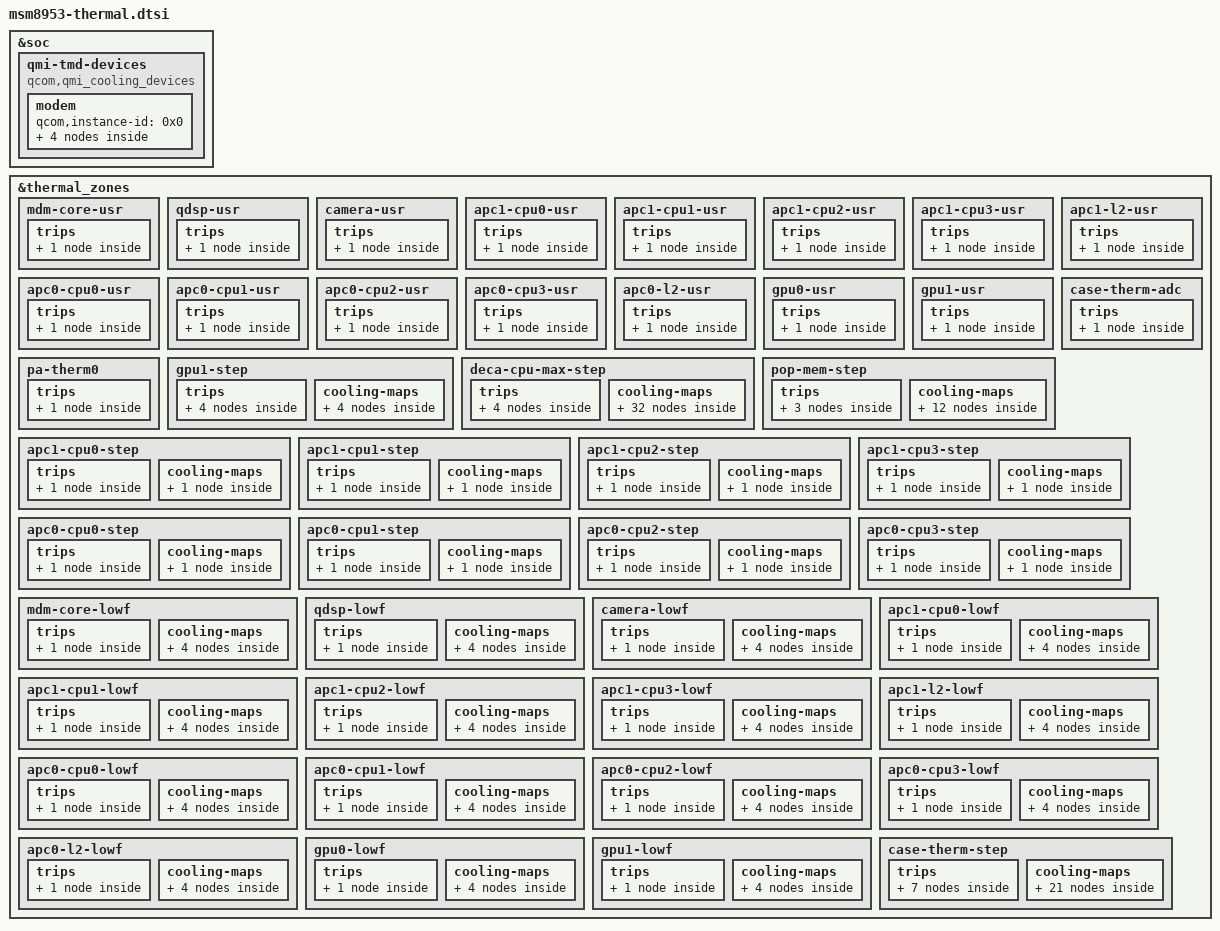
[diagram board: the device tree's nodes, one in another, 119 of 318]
/* Copyright (c) 2018, The Linux Foundation. All rights reserved.
 *
 * This program is free software; you can redistribute it and/or modify
 * it under the terms of the GNU General Public License version 2 and
 * only version 2 as published by the Free Software Foundation.
 *
 * This program is distributed in the hope that it will be useful,
 * but WITHOUT ANY WARRANTY; without even the implied warranty of
 * MERCHANTABILITY or FITNESS FOR A PARTICULAR PURPOSE.  See the
 * GNU General Public License for more details.
 *
 * Optimized thermal configuration for MSM8953
 * Multi-step throttling for smooth performance
 */

#include <dt-bindings/thermal/thermal.h>

&soc {
	qmi-tmd-devices {
		compatible = "qcom,qmi_cooling_devices";

		modem {
			qcom,instance-id = <0x0>;

			modem_pa: modem_pa {
				qcom,qmi-dev-name = "pa";
				#cooling-cells = <2>;
			};

			modem_proc: modem_proc {
				qcom,qmi-dev-name = "modem";
				#cooling-cells = <2>;
			};

			modem_current: modem_current {
				qcom,qmi-dev-name = "modem_current";
				#cooling-cells = <2>;
			};

			modem_vdd: modem_vdd {
				qcom,qmi-dev-name = "cpuv_restriction_cold";
				#cooling-cells = <2>;
			};
		};
	};
};

&thermal_zones {

	/* ═══════════════════════════════════════════════════════════════════
	 * USER-SPACE SENSORS (для чтения приложениями)
	 * ═══════════════════════════════════════════════════════════════════ */

	mdm-core-usr {
		polling-delay-passive = <0>;
		polling-delay = <0>;
		thermal-governor = "user_space";
		thermal-sensors = <&tsens0 1>;
		trips {
			active-config0 {
				temperature = <125000>;
				hysteresis = <1000>;
				type = "passive";
			};
		};
	};

	qdsp-usr {
		polling-delay-passive = <0>;
		polling-delay = <0>;
		thermal-governor = "user_space";
		thermal-sensors = <&tsens0 2>;
		trips {
			active-config0 {
				temperature = <125000>;
				hysteresis = <1000>;
				type = "passive";
			};
		};
	};

	camera-usr {
		polling-delay-passive = <0>;
		polling-delay = <0>;
		thermal-governor = "user_space";
		thermal-sensors = <&tsens0 3>;
		trips {
			active-config0 {
				temperature = <125000>;
				hysteresis = <1000>;
				type = "passive";
			};
		};
	};

	apc1-cpu0-usr {
		polling-delay-passive = <0>;
		polling-delay = <0>;
		thermal-sensors = <&tsens0 4>;
		thermal-governor = "user_space";
		trips {
			active-config0 {
				temperature = <125000>;
				hysteresis = <1000>;
				type = "passive";
			};
		};
	};

	apc1-cpu1-usr {
		polling-delay-passive = <0>;
		polling-delay = <0>;
		thermal-sensors = <&tsens0 5>;
		thermal-governor = "user_space";
		trips {
			active-config0 {
				temperature = <125000>;
				hysteresis = <1000>;
				type = "passive";
			};
		};
	};

	apc1-cpu2-usr {
		polling-delay-passive = <0>;
		polling-delay = <0>;
		thermal-sensors = <&tsens0 6>;
		thermal-governor = "user_space";
		trips {
			active-config0 {
				temperature = <125000>;
				hysteresis = <1000>;
				type = "passive";
			};
		};
	};

	apc1-cpu3-usr {
		polling-delay-passive = <0>;
		polling-delay = <0>;
		thermal-sensors = <&tsens0 7>;
		thermal-governor = "user_space";
		trips {
			active-config0 {
				temperature = <125000>;
				hysteresis = <1000>;
				type = "passive";
			};
		};
	};

	apc1-l2-usr {
		polling-delay-passive = <0>;
		polling-delay = <0>;
		thermal-sensors = <&tsens0 8>;
		thermal-governor = "user_space";
		trips {
			active-config0 {
				temperature = <125000>;
				hysteresis = <1000>;
				type = "passive";
			};
		};
	};

	apc0-cpu0-usr {
		polling-delay-passive = <0>;
		polling-delay = <0>;
		thermal-sensors = <&tsens0 9>;
		thermal-governor = "user_space";
		trips {
			active-config0 {
				temperature = <125000>;
				hysteresis = <1000>;
				type = "passive";
			};
		};
	};

	apc0-cpu1-usr {
		polling-delay-passive = <0>;
		polling-delay = <0>;
		thermal-sensors = <&tsens0 10>;
		thermal-governor = "user_space";
		trips {
			active-config0 {
				temperature = <125000>;
				hysteresis = <1000>;
				type = "passive";
			};
		};
	};

	apc0-cpu2-usr {
		polling-delay-passive = <0>;
		polling-delay = <0>;
		thermal-sensors = <&tsens0 11>;
		thermal-governor = "user_space";
		trips {
			active-config0 {
				temperature = <125000>;
				hysteresis = <1000>;
				type = "passive";
			};
		};
	};

	apc0-cpu3-usr {
		polling-delay-passive = <0>;
		polling-delay = <0>;
		thermal-sensors = <&tsens0 12>;
		thermal-governor = "user_space";
		trips {
			active-config0 {
				temperature = <125000>;
				hysteresis = <1000>;
				type = "passive";
			};
		};
	};

	apc0-l2-usr {
		polling-delay-passive = <0>;
		polling-delay = <0>;
		thermal-sensors = <&tsens0 13>;
		thermal-governor = "user_space";
		trips {
			active-config0 {
				temperature = <125000>;
				hysteresis = <1000>;
				type = "passive";
			};
		};
	};

	gpu0-usr {
		polling-delay-passive = <0>;
		polling-delay = <0>;
		thermal-sensors = <&tsens0 14>;
		thermal-governor = "user_space";
		trips {
			active-config0 {
				temperature = <125000>;
				hysteresis = <1000>;
				type = "passive";
			};
		};
	};

	gpu1-usr {
		polling-delay-passive = <0>;
		polling-delay = <0>;
		thermal-sensors = <&tsens0 15>;
		thermal-governor = "user_space";
		trips {
			active-config0 {
				temperature = <125000>;
				hysteresis = <1000>;
				type = "passive";
			};
		};
	};

	case-therm-adc {
		polling-delay-passive = <0>;
		polling-delay = <0>;
		thermal-sensors = <&pm8953_vadc 0x13>;
		thermal-governor = "user_space";
		trips {
			active-config0 {
				temperature = <65000>;
				hysteresis = <1000>;
				type = "passive";
			};
		};
	};

	pa-therm0 {
		polling-delay-passive = <0>;
		polling-delay = <0>;
		thermal-sensors = <&pm8953_adc_tm 0x36>;
		thermal-governor = "user_space";
		trips {
			active-config0 {
				temperature = <65000>;
				hysteresis = <5000>;
				type = "passive";
			};
		};
	};

	/* ═══════════════════════════════════════════════════════════════════
	 * GPU MULTI-STEP THROTTLING (IMPROVED)
	 * Плавное снижение частоты GPU при нагреве
	 * ═══════════════════════════════════════════════════════════════════ */

	gpu1-step {
		polling-delay-passive = <100>;
		polling-delay = <0>;
		thermal-sensors = <&tsens0 15>;
		thermal-governor = "step_wise";

		trips {
			gpu_trip_mild: gpu-trip-mild {
				temperature = <70000>;
				hysteresis = <3000>;
				type = "passive";
			};

			gpu_trip_moderate: gpu-trip-moderate {
				temperature = <80000>;
				hysteresis = <3000>;
				type = "passive";
			};

			gpu_trip_heavy: gpu-trip-heavy {
				temperature = <90000>;
				hysteresis = <3000>;
				type = "passive";
			};

			gpu_trip0: gpu-trip0 {
				temperature = <95000>;
				hysteresis = <0>;
				type = "passive";
			};
		};

		cooling-maps {
			gpu_cdev_mild {
				trip = <&gpu_trip_mild>;
				cooling-device = <&msm_gpu 1 1>;
			};

			gpu_cdev_moderate {
				trip = <&gpu_trip_moderate>;
				cooling-device = <&msm_gpu 2 3>;
			};

			gpu_cdev_heavy {
				trip = <&gpu_trip_heavy>;
				cooling-device = <&msm_gpu 3 4>;
			};

			gpu_cdev0 {
				trip = <&gpu_trip0>;
				cooling-device = <&msm_gpu THERMAL_NO_LIMIT THERMAL_NO_LIMIT>;
			};
		};
	};

	/* ═══════════════════════════════════════════════════════════════════
	 * CPU MULTI-STEP THROTTLING (IMPROVED)
	 * Плавный throttling начинается с 65°C вместо 95°C
	 * ═══════════════════════════════════════════════════════════════════ */

	deca-cpu-max-step {
		polling-delay-passive = <50>;
		polling-delay = <100>;
		thermal-governor = "step_wise";

		trips {
			/* Мягкий throttling - 65°C */
			cpu_trip_mild: cpu-trip-mild {
				temperature = <65000>;
				hysteresis = <3000>;
				type = "passive";
			};

			/* Умеренный throttling - 75°C */
			cpu_trip_moderate: cpu-trip-moderate {
				temperature = <75000>;
				hysteresis = <3000>;
				type = "passive";
			};

			/* Сильный throttling - 85°C */
			cpu_trip_heavy: cpu-trip-heavy {
				temperature = <85000>;
				hysteresis = <3000>;
				type = "passive";
			};

			/* Критический - 95°C */
			cpu_trip: cpu-trip {
				temperature = <95000>;
				hysteresis = <0>;
				type = "passive";
			};
		};

		cooling-maps {
			/* ══════ 65-75°C: Мягкое ограничение (state 0-2) ══════ */
			/* Ограничение до ~1958 MHz */
			cpu0_mild {
				trip = <&cpu_trip_mild>;
				cooling-device = <&CPU0 0 2>;
			};
			cpu1_mild {
				trip = <&cpu_trip_mild>;
				cooling-device = <&CPU1 0 2>;
			};
			cpu2_mild {
				trip = <&cpu_trip_mild>;
				cooling-device = <&CPU2 0 2>;
			};
			cpu3_mild {
				trip = <&cpu_trip_mild>;
				cooling-device = <&CPU3 0 2>;
			};
			cpu4_mild {
				trip = <&cpu_trip_mild>;
				cooling-device = <&CPU4 0 2>;
			};
			cpu5_mild {
				trip = <&cpu_trip_mild>;
				cooling-device = <&CPU5 0 2>;
			};
			cpu6_mild {
				trip = <&cpu_trip_mild>;
				cooling-device = <&CPU6 0 2>;
			};
			cpu7_mild {
				trip = <&cpu_trip_mild>;
				cooling-device = <&CPU7 0 2>;
			};

			/* ══════ 75-85°C: Умеренное ограничение (state 2-5) ══════ */
			/* Ограничение до ~1689 MHz */
			cpu0_moderate {
				trip = <&cpu_trip_moderate>;
				cooling-device = <&CPU0 2 5>;
			};
			cpu1_moderate {
				trip = <&cpu_trip_moderate>;
				cooling-device = <&CPU1 2 5>;
			};
			cpu2_moderate {
				trip = <&cpu_trip_moderate>;
				cooling-device = <&CPU2 2 5>;
			};
			cpu3_moderate {
				trip = <&cpu_trip_moderate>;
				cooling-device = <&CPU3 2 5>;
			};
			cpu4_moderate {
				trip = <&cpu_trip_moderate>;
				cooling-device = <&CPU4 2 5>;
			};
			cpu5_moderate {
				trip = <&cpu_trip_moderate>;
				cooling-device = <&CPU5 2 5>;
			};
			cpu6_moderate {
				trip = <&cpu_trip_moderate>;
				cooling-device = <&CPU6 2 5>;
			};
			cpu7_moderate {
				trip = <&cpu_trip_moderate>;
				cooling-device = <&CPU7 2 5>;
			};

			/* ══════ 85-95°C: Сильное ограничение (state 5-8) ══════ */
			/* Ограничение до ~1248 MHz */
			cpu0_heavy {
				trip = <&cpu_trip_heavy>;
				cooling-device = <&CPU0 5 8>;
			};
			cpu1_heavy {
				trip = <&cpu_trip_heavy>;
				cooling-device = <&CPU1 5 8>;
			};
			cpu2_heavy {
				trip = <&cpu_trip_heavy>;
				cooling-device = <&CPU2 5 8>;
			};
			cpu3_heavy {
				trip = <&cpu_trip_heavy>;
				cooling-device = <&CPU3 5 8>;
			};
			cpu4_heavy {
				trip = <&cpu_trip_heavy>;
				cooling-device = <&CPU4 5 8>;
			};
			cpu5_heavy {
				trip = <&cpu_trip_heavy>;
				cooling-device = <&CPU5 5 8>;
			};
			cpu6_heavy {
				trip = <&cpu_trip_heavy>;
				cooling-device = <&CPU6 5 8>;
			};
			cpu7_heavy {
				trip = <&cpu_trip_heavy>;
				cooling-device = <&CPU7 5 8>;
			};

			/* ══════ 95°C+: Критическое ограничение ══════ */
			cpu0_cdev {
				trip = <&cpu_trip>;
				cooling-device = <&CPU0 THERMAL_NO_LIMIT (THERMAL_MAX_LIMIT-1)>;
			};
			cpu1_cdev {
				trip = <&cpu_trip>;
				cooling-device = <&CPU1 THERMAL_NO_LIMIT (THERMAL_MAX_LIMIT-1)>;
			};
			cpu2_cdev {
				trip = <&cpu_trip>;
				cooling-device = <&CPU2 THERMAL_NO_LIMIT (THERMAL_MAX_LIMIT-1)>;
			};
			cpu3_cdev {
				trip = <&cpu_trip>;
				cooling-device = <&CPU3 THERMAL_NO_LIMIT (THERMAL_MAX_LIMIT-1)>;
			};
			cpu4_cdev {
				trip = <&cpu_trip>;
				cooling-device = <&CPU4 THERMAL_NO_LIMIT (THERMAL_MAX_LIMIT-1)>;
			};
			cpu5_cdev {
				trip = <&cpu_trip>;
				cooling-device = <&CPU5 THERMAL_NO_LIMIT (THERMAL_MAX_LIMIT-1)>;
			};
			cpu6_cdev {
				trip = <&cpu_trip>;
				cooling-device = <&CPU6 THERMAL_NO_LIMIT (THERMAL_MAX_LIMIT-1)>;
			};
			cpu7_cdev {
				trip = <&cpu_trip>;
				cooling-device = <&CPU7 THERMAL_NO_LIMIT (THERMAL_MAX_LIMIT-1)>;
			};
		};
	};

	/* ═══════════════════════════════════════════════════════════════════
	 * MEMORY/POP THERMAL (IMPROVED)
	 * ═══════════════════════════════════════════════════════════════════ */

	pop-mem-step {
		polling-delay-passive = <250>;
		polling-delay = <0>;
		thermal-sensors = <&tsens0 2>;
		thermal-governor = "step_wise";

		trips {
			pop_trip_mild: pop-trip-mild {
				temperature = <75000>;
				hysteresis = <3000>;
				type = "passive";
			};

			pop_trip_moderate: pop-trip-moderate {
				temperature = <85000>;
				hysteresis = <3000>;
				type = "passive";
			};

			pop_trip: pop-trip {
				temperature = <95000>;
				hysteresis = <0>;
				type = "passive";
			};
		};

		cooling-maps {
			pop_cdev0_mild {
				trip = <&pop_trip_mild>;
				cooling-device = <&CPU0 0 3>;
			};
			pop_cdev4_mild {
				trip = <&pop_trip_mild>;
				cooling-device = <&CPU4 0 3>;
			};

			pop_cdev0_moderate {
				trip = <&pop_trip_moderate>;
				cooling-device = <&CPU0 3 6>;
			};
			pop_cdev4_moderate {
				trip = <&pop_trip_moderate>;
				cooling-device = <&CPU4 3 6>;
			};

			pop_cdev0 {
				trip = <&pop_trip>;
				cooling-device = <&CPU0 THERMAL_NO_LIMIT (THERMAL_MAX_LIMIT-1)>;
			};
			pop_cdev1 {
				trip = <&pop_trip>;
				cooling-device = <&CPU1 THERMAL_NO_LIMIT (THERMAL_MAX_LIMIT-1)>;
			};
			pop_cdev2 {
				trip = <&pop_trip>;
				cooling-device = <&CPU2 THERMAL_NO_LIMIT (THERMAL_MAX_LIMIT-1)>;
			};
			pop_cdev3 {
				trip = <&pop_trip>;
				cooling-device = <&CPU3 THERMAL_NO_LIMIT (THERMAL_MAX_LIMIT-1)>;
			};
			pop_cdev4 {
				trip = <&pop_trip>;
				cooling-device = <&CPU4 THERMAL_NO_LIMIT (THERMAL_MAX_LIMIT-1)>;
			};
			pop_cdev5 {
				trip = <&pop_trip>;
				cooling-device = <&CPU5 THERMAL_NO_LIMIT (THERMAL_MAX_LIMIT-1)>;
			};
			pop_cdev6 {
				trip = <&pop_trip>;
				cooling-device = <&CPU6 THERMAL_NO_LIMIT (THERMAL_MAX_LIMIT-1)>;
			};
			pop_cdev7 {
				trip = <&pop_trip>;
				cooling-device = <&CPU7 THERMAL_NO_LIMIT (THERMAL_MAX_LIMIT-1)>;
			};
		};
	};

	/* ═══════════════════════════════════════════════════════════════════
	 * PER-CPU EMERGENCY THROTTLING (IMPROVED)
	 * Порог снижен до 100°C для безопасности
	 * ═══════════════════════════════════════════════════════════════════ */

	apc1-cpu0-step {
		polling-delay-passive = <0>;
		polling-delay = <0>;
		thermal-sensors = <&tsens0 4>;
		thermal-governor = "step_wise";
		trips {
			apc1_cpu0_trip: apc1-cpu0-trip {
				temperature = <100000>;
				hysteresis = <10000>;
				type = "passive";
			};
		};
		cooling-maps {
			cpu4_cdev {
				trip = <&apc1_cpu0_trip>;
				cooling-device = <&CPU4 THERMAL_MAX_LIMIT THERMAL_MAX_LIMIT>;
			};
		};
	};

	apc1-cpu1-step {
		polling-delay-passive = <0>;
		polling-delay = <0>;
		thermal-sensors = <&tsens0 5>;
		thermal-governor = "step_wise";
		trips {
			apc1_cpu1_trip: apc1-cpu1-trip {
				temperature = <100000>;
				hysteresis = <10000>;
				type = "passive";
			};
		};
		cooling-maps {
			cpu5_cdev {
				trip = <&apc1_cpu1_trip>;
				cooling-device = <&CPU5 THERMAL_MAX_LIMIT THERMAL_MAX_LIMIT>;
			};
		};
	};

	apc1-cpu2-step {
		polling-delay-passive = <0>;
		polling-delay = <0>;
		thermal-sensors = <&tsens0 6>;
		thermal-governor = "step_wise";
		trips {
			apc1_cpu2_trip: apc1-cpu2-trip {
				temperature = <100000>;
				hysteresis = <10000>;
				type = "passive";
			};
		};
		cooling-maps {
			cpu6_cdev {
				trip = <&apc1_cpu2_trip>;
				cooling-device = <&CPU6 THERMAL_MAX_LIMIT THERMAL_MAX_LIMIT>;
			};
		};
	};

	apc1-cpu3-step {
		polling-delay-passive = <0>;
		polling-delay = <0>;
		thermal-sensors = <&tsens0 7>;
		thermal-governor = "step_wise";
		trips {
			apc1_cpu3_trip: apc1-cpu3-trip {
				temperature = <100000>;
				hysteresis = <10000>;
				type = "passive";
			};
		};
		cooling-maps {
			cpu7_cdev {
				trip = <&apc1_cpu3_trip>;
				cooling-device = <&CPU7 THERMAL_MAX_LIMIT THERMAL_MAX_LIMIT>;
			};
		};
	};

	apc0-cpu0-step {
		polling-delay-passive = <0>;
		polling-delay = <0>;
		thermal-sensors = <&tsens0 9>;
		thermal-governor = "step_wise";
		trips {
			apc0_cpu0_trip: apc0-cpu0-trip {
				temperature = <100000>;
				hysteresis = <10000>;
				type = "passive";
			};
		};
		cooling-maps {
			cpu0_cdev {
				trip = <&apc0_cpu0_trip>;
				cooling-device = <&CPU0 THERMAL_MAX_LIMIT THERMAL_MAX_LIMIT>;
			};
		};
	};

	apc0-cpu1-step {
		polling-delay-passive = <0>;
		polling-delay = <0>;
		thermal-sensors = <&tsens0 10>;
		thermal-governor = "step_wise";
		trips {
			apc0_cpu1_trip: apc0-cpu1-trip {
				temperature = <100000>;
				hysteresis = <10000>;
				type = "passive";
			};
		};
		cooling-maps {
			cpu1_cdev {
				trip = <&apc0_cpu1_trip>;
				cooling-device = <&CPU1 THERMAL_MAX_LIMIT THERMAL_MAX_LIMIT>;
			};
		};
	};

	apc0-cpu2-step {
		polling-delay-passive = <0>;
		polling-delay = <0>;
		thermal-sensors = <&tsens0 11>;
		thermal-governor = "step_wise";
		trips {
			apc0_cpu2_trip: apc0-cpu2-trip {
				temperature = <100000>;
				hysteresis = <10000>;
				type = "passive";
			};
		};
		cooling-maps {
			cpu2_cdev {
				trip = <&apc0_cpu2_trip>;
				cooling-device = <&CPU2 THERMAL_MAX_LIMIT THERMAL_MAX_LIMIT>;
			};
		};
	};

	apc0-cpu3-step {
		polling-delay-passive = <0>;
		polling-delay = <0>;
		thermal-sensors = <&tsens0 12>;
		thermal-governor = "step_wise";
		trips {
			apc0_cpu3_trip: apc0-cpu3-trip {
				temperature = <100000>;
				hysteresis = <10000>;
				type = "passive";
			};
		};
		cooling-maps {
			cpu3_cdev {
				trip = <&apc0_cpu3_trip>;
				cooling-device = <&CPU3 THERMAL_MAX_LIMIT THERMAL_MAX_LIMIT>;
			};
		};
	};

	/* ═══════════════════════════════════════════════════════════════════
	 * LOW TEMPERATURE FLOOR PROTECTION
	 * Защита от работы на слишком низких температурах
	 * ═══════════════════════════════════════════════════════════════════ */

	mdm-core-lowf {
		polling-delay-passive = <0>;
		polling-delay = <0>;
		thermal-governor = "low_limits_floor";
		thermal-sensors = <&tsens0 1>;
		tracks-low;
		trips {
			mdm_core_trip: mdm-core-trip {
				temperature = <5000>;
				hysteresis = <5000>;
				type = "passive";
			};
		};
		cooling-maps {
			cpu0_vdd_cdev {
				trip = <&mdm_core_trip>;
				cooling-device = <&CPU0 (THERMAL_MAX_LIMIT - 4)
						(THERMAL_MAX_LIMIT - 4)>;
			};
			gpu_vdd_cdev {
				trip = <&mdm_core_trip>;
				cooling-device = <&msm_gpu 2 2>;
			};
			cx_vdd_cdev {
				trip = <&mdm_core_trip>;
				cooling-device = <&cx_cdev 0 0>;
			};
			modem_vdd_cdev {
				trip = <&mdm_core_trip>;
				cooling-device = <&modem_vdd 0 0>;
			};
		};
	};

	qdsp-lowf {
		polling-delay-passive = <0>;
		polling-delay = <0>;
		thermal-governor = "low_limits_floor";
		thermal-sensors = <&tsens0 2>;
		tracks-low;
		trips {
			qdsp_trip: qdsp-trip {
				temperature = <5000>;
				hysteresis = <5000>;
				type = "passive";
			};
		};
		cooling-maps {
			cpu0_vdd_cdev {
				trip = <&qdsp_trip>;
				cooling-device = <&CPU0 (THERMAL_MAX_LIMIT - 4)
						(THERMAL_MAX_LIMIT - 4)>;
			};
			gpu_vdd_cdev {
				trip = <&qdsp_trip>;
				cooling-device = <&msm_gpu 2 2>;
			};
			cx_vdd_cdev {
				trip = <&qdsp_trip>;
				cooling-device = <&cx_cdev 0 0>;
			};
			modem_vdd_cdev {
				trip = <&qdsp_trip>;
				cooling-device = <&modem_vdd 0 0>;
			};
		};
	};

	camera-lowf {
		polling-delay-passive = <0>;
		polling-delay = <0>;
		thermal-governor = "low_limits_floor";
		thermal-sensors = <&tsens0 3>;
		tracks-low;
		trips {
			camera_trip: camera-trip {
				temperature = <5000>;
				hysteresis = <5000>;
				type = "passive";
			};
		};
		cooling-maps {
			cpu0_vdd_cdev {
				trip = <&camera_trip>;
				cooling-device = <&CPU0 (THERMAL_MAX_LIMIT - 4)
						(THERMAL_MAX_LIMIT - 4)>;
			};
			gpu_vdd_cdev {
				trip = <&camera_trip>;
				cooling-device = <&msm_gpu 2 2>;
			};
			cx_vdd_cdev {
				trip = <&camera_trip>;
				cooling-device = <&cx_cdev 0 0>;
			};
			modem_vdd_cdev {
				trip = <&camera_trip>;
				cooling-device = <&modem_vdd 0 0>;
			};
		};
	};

	apc1-cpu0-lowf {
		polling-delay-passive = <0>;
		polling-delay = <0>;
		thermal-governor = "low_limits_floor";
		thermal-sensors = <&tsens0 4>;
		tracks-low;
		trips {
			cpu4_trip: apc1-cpu0-trip {
				temperature = <5000>;
				hysteresis = <5000>;
				type = "passive";
			};
		};
		cooling-maps {
			cpu0_vdd_cdev {
				trip = <&cpu4_trip>;
				cooling-device = <&CPU0 (THERMAL_MAX_LIMIT - 4)
						(THERMAL_MAX_LIMIT - 4)>;
			};
			gpu_vdd_cdev {
				trip = <&cpu4_trip>;
				cooling-device = <&msm_gpu 2 2>;
			};
			cx_vdd_cdev {
				trip = <&cpu4_trip>;
				cooling-device = <&cx_cdev 0 0>;
			};
			modem_vdd_cdev {
				trip = <&cpu4_trip>;
				cooling-device = <&modem_vdd 0 0>;
			};
		};
	};

	apc1-cpu1-lowf {
		polling-delay-passive = <0>;
		polling-delay = <0>;
		thermal-governor = "low_limits_floor";
		thermal-sensors = <&tsens0 5>;
		tracks-low;
		trips {
			cpu5_trip: apc1-cpu0-trip {
				temperature = <5000>;
				hysteresis = <5000>;
				type = "passive";
			};
		};
		cooling-maps {
			cpu0_vdd_cdev {
				trip = <&cpu5_trip>;
				cooling-device = <&CPU0 (THERMAL_MAX_LIMIT - 4)
						(THERMAL_MAX_LIMIT - 4)>;
			};
			gpu_vdd_cdev {
				trip = <&cpu5_trip>;
				cooling-device = <&msm_gpu 2 2>;
			};
			cx_vdd_cdev {
				trip = <&cpu5_trip>;
				cooling-device = <&cx_cdev 0 0>;
			};
			modem_vdd_cdev {
				trip = <&cpu5_trip>;
				cooling-device = <&modem_vdd 0 0>;
			};
		};
	};

	apc1-cpu2-lowf {
		polling-delay-passive = <0>;
		polling-delay = <0>;
		thermal-governor = "low_limits_floor";
		thermal-sensors = <&tsens0 6>;
		tracks-low;
		trips {
			cpu6_trip: apc1-cpu2-trip {
				temperature = <5000>;
				hysteresis = <5000>;
				type = "passive";
			};
		};
		cooling-maps {
			cpu0_vdd_cdev {
				trip = <&cpu6_trip>;
				cooling-device = <&CPU0 (THERMAL_MAX_LIMIT - 4)
						(THERMAL_MAX_LIMIT - 4)>;
			};
			gpu_vdd_cdev {
				trip = <&cpu6_trip>;
				cooling-device = <&msm_gpu 2 2>;
			};
			cx_vdd_cdev {
				trip = <&cpu6_trip>;
				cooling-device = <&cx_cdev 0 0>;
			};
			modem_vdd_cdev {
				trip = <&cpu6_trip>;
				cooling-device = <&modem_vdd 0 0>;
			};
		};
	};

	apc1-cpu3-lowf {
		polling-delay-passive = <0>;
		polling-delay = <0>;
		thermal-governor = "low_limits_floor";
		thermal-sensors = <&tsens0 7>;
		tracks-low;
		trips {
			cpu7_trip: apc1-cpu3-trip {
				temperature = <5000>;
				hysteresis = <5000>;
				type = "passive";
			};
		};
		cooling-maps {
			cpu0_vdd_cdev {
				trip = <&cpu7_trip>;
				cooling-device = <&CPU0 (THERMAL_MAX_LIMIT - 4)
						(THERMAL_MAX_LIMIT - 4)>;
			};
			gpu_vdd_cdev {
				trip = <&cpu7_trip>;
				cooling-device = <&msm_gpu 2 2>;
			};
			cx_vdd_cdev {
				trip = <&cpu7_trip>;
				cooling-device = <&cx_cdev 0 0>;
			};
			modem_vdd_cdev {
				trip = <&cpu7_trip>;
				cooling-device = <&modem_vdd 0 0>;
			};
		};
	};

	apc1-l2-lowf {
		polling-delay-passive = <0>;
		polling-delay = <0>;
		thermal-governor = "low_limits_floor";
		thermal-sensors = <&tsens0 8>;
		tracks-low;
		trips {
			apc1_l2_trip: apc1-l2-trip {
				temperature = <5000>;
				hysteresis = <5000>;
				type = "passive";
			};
		};
		cooling-maps {
			cpu0_vdd_cdev {
				trip = <&apc1_l2_trip>;
				cooling-device = <&CPU0 (THERMAL_MAX_LIMIT - 4)
						(THERMAL_MAX_LIMIT - 4)>;
			};
			gpu_vdd_cdev {
				trip = <&apc1_l2_trip>;
				cooling-device = <&msm_gpu 2 2>;
			};
			cx_vdd_cdev {
				trip = <&apc1_l2_trip>;
				cooling-device = <&cx_cdev 0 0>;
			};
			modem_vdd_cdev {
				trip = <&apc1_l2_trip>;
				cooling-device = <&modem_vdd 0 0>;
			};
		};
	};

	apc0-cpu0-lowf {
		polling-delay-passive = <0>;
		polling-delay = <0>;
		thermal-governor = "low_limits_floor";
		thermal-sensors = <&tsens0 9>;
		tracks-low;
		trips {
			cpu0_trip: apc0-cpu0-trip {
				temperature = <5000>;
				hysteresis = <5000>;
				type = "passive";
			};
		};
		cooling-maps {
			cpu0_vdd_cdev {
				trip = <&cpu0_trip>;
				cooling-device = <&CPU0 (THERMAL_MAX_LIMIT - 4)
						(THERMAL_MAX_LIMIT - 4)>;
			};
			gpu_vdd_cdev {
				trip = <&cpu0_trip>;
				cooling-device = <&msm_gpu 2 2>;
			};
			cx_vdd_cdev {
				trip = <&cpu0_trip>;
				cooling-device = <&cx_cdev 0 0>;
			};
			modem_vdd_cdev {
				trip = <&cpu0_trip>;
				cooling-device = <&modem_vdd 0 0>;
			};
		};
	};

	apc0-cpu1-lowf {
		polling-delay-passive = <0>;
		polling-delay = <0>;
		thermal-governor = "low_limits_floor";
		thermal-sensors = <&tsens0 10>;
		tracks-low;
		trips {
			cpu1_trip: apc0-cpu1-trip {
				temperature = <5000>;
				hysteresis = <5000>;
				type = "passive";
			};
		};
		cooling-maps {
			cpu0_vdd_cdev {
				trip = <&cpu1_trip>;
				cooling-device = <&CPU0 (THERMAL_MAX_LIMIT - 4)
						(THERMAL_MAX_LIMIT - 4)>;
			};
			gpu_vdd_cdev {
				trip = <&cpu1_trip>;
				cooling-device = <&msm_gpu 2 2>;
			};
			cx_vdd_cdev {
				trip = <&cpu1_trip>;
				cooling-device = <&cx_cdev 0 0>;
			};
			modem_vdd_cdev {
				trip = <&cpu1_trip>;
				cooling-device = <&modem_vdd 0 0>;
			};
		};
	};

	apc0-cpu2-lowf {
		polling-delay-passive = <0>;
		polling-delay = <0>;
		thermal-governor = "low_limits_floor";
		thermal-sensors = <&tsens0 11>;
		tracks-low;
		trips {
			cpu2_trip: apc0-cpu2-trip {
				temperature = <5000>;
				hysteresis = <5000>;
				type = "passive";
			};
		};
		cooling-maps {
			cpu0_vdd_cdev {
				trip = <&cpu2_trip>;
				cooling-device = <&CPU0 (THERMAL_MAX_LIMIT - 4)
						(THERMAL_MAX_LIMIT - 4)>;
			};
			gpu_vdd_cdev {
				trip = <&cpu2_trip>;
				cooling-device = <&msm_gpu 2 2>;
			};
			cx_vdd_cdev {
				trip = <&cpu2_trip>;
				cooling-device = <&cx_cdev 0 0>;
			};
			modem_vdd_cdev {
				trip = <&cpu2_trip>;
				cooling-device = <&modem_vdd 0 0>;
			};
		};
	};

	apc0-cpu3-lowf {
		polling-delay-passive = <0>;
		polling-delay = <0>;
		thermal-governor = "low_limits_floor";
		thermal-sensors = <&tsens0 12>;
		tracks-low;
		trips {
			cpu3_trip: apc0-cpu3-trip {
				temperature = <5000>;
				hysteresis = <5000>;
				type = "passive";
			};
		};
		cooling-maps {
			cpu0_vdd_cdev {
				trip = <&cpu3_trip>;
				cooling-device = <&CPU0 (THERMAL_MAX_LIMIT - 4)
						(THERMAL_MAX_LIMIT - 4)>;
			};
			gpu_vdd_cdev {
				trip = <&cpu3_trip>;
				cooling-device = <&msm_gpu 2 2>;
			};
			cx_vdd_cdev {
				trip = <&cpu3_trip>;
				cooling-device = <&cx_cdev 0 0>;
			};
			modem_vdd_cdev {
				trip = <&cpu3_trip>;
				cooling-device = <&modem_vdd 0 0>;
			};
		};
	};

	apc0-l2-lowf {
		polling-delay-passive = <0>;
		polling-delay = <0>;
		thermal-governor = "low_limits_floor";
		thermal-sensors = <&tsens0 13>;
		tracks-low;
		trips {
			apc0_l2_trip: apc0-l2-trip {
				temperature = <5000>;
				hysteresis = <5000>;
				type = "passive";
			};
		};
		cooling-maps {
			cpu0_vdd_cdev {
				trip = <&apc0_l2_trip>;
				cooling-device = <&CPU0 (THERMAL_MAX_LIMIT - 4)
						(THERMAL_MAX_LIMIT - 4)>;
			};
			gpu_vdd_cdev {
				trip = <&apc0_l2_trip>;
				cooling-device = <&msm_gpu 2 2>;
			};
			cx_vdd_cdev {
				trip = <&apc0_l2_trip>;
				cooling-device = <&cx_cdev 0 0>;
			};
			modem_vdd_cdev {
				trip = <&apc0_l2_trip>;
				cooling-device = <&modem_vdd 0 0>;
			};
		};
	};

	gpu0-lowf {
		polling-delay-passive = <0>;
		polling-delay = <0>;
		thermal-governor = "low_limits_floor";
		thermal-sensors = <&tsens0 14>;
		tracks-low;
		trips {
			gpu0_trip: gpu0-trip {
				temperature = <5000>;
				hysteresis = <5000>;
				type = "passive";
			};
		};
		cooling-maps {
			cpu0_vdd_cdev {
				trip = <&gpu0_trip>;
				cooling-device = <&CPU0 (THERMAL_MAX_LIMIT - 4)
						(THERMAL_MAX_LIMIT - 4)>;
			};
			gpu_vdd_cdev {
				trip = <&gpu0_trip>;
				cooling-device = <&msm_gpu 2 2>;
			};
			cx_vdd_cdev {
				trip = <&gpu0_trip>;
				cooling-device = <&cx_cdev 0 0>;
			};
			modem_vdd_cdev {
				trip = <&gpu0_trip>;
				cooling-device = <&modem_vdd 0 0>;
			};
		};
	};

	gpu1-lowf {
		polling-delay-passive = <0>;
		polling-delay = <0>;
		thermal-governor = "low_limits_floor";
		thermal-sensors = <&tsens0 15>;
		tracks-low;
		trips {
			gpu1_trip: gpu1-trip {
				temperature = <5000>;
				hysteresis = <5000>;
				type = "passive";
			};
		};
		cooling-maps {
			cpu0_vdd_cdev {
				trip = <&gpu1_trip>;
				cooling-device = <&CPU0 (THERMAL_MAX_LIMIT - 4)
						(THERMAL_MAX_LIMIT - 4)>;
			};
			gpu_vdd_cdev {
				trip = <&gpu1_trip>;
				cooling-device = <&msm_gpu 2 2>;
			};
			cx_vdd_cdev {
				trip = <&gpu1_trip>;
				cooling-device = <&cx_cdev 0 0>;
			};
			modem_vdd_cdev {
				trip = <&gpu1_trip>;
				cooling-device = <&modem_vdd 0 0>;
			};
		};
	};

	/* ═══════════════════════════════════════════════════════════════════
	 * CASE/SKIN THERMAL (IMPROVED)
	 * Плавный throttling на основе температуры корпуса
	 * ═══════════════════════════════════════════════════════════════════ */

	case-therm-step {
		polling-delay-passive = <1000>;
		polling-delay = <0>;
		thermal-sensors = <&pm8953_vadc 0x13>;
		thermal-governor = "step_wise";

		trips {
			/* Раннее предупреждение - 45°C на корпусе */
			skin_trip_early: skin-trip-early {
				temperature = <45000>;
				hysteresis = <2000>;
				type = "passive";
			};

			/* Мягкое ограничение - 50°C на корпусе */
			skin_trip_mild: skin-trip-mild {
				temperature = <50000>;
				hysteresis = <2000>;
				type = "passive";
			};

			/* Умеренное ограничение - 55°C */
			skin_trip_moderate: skin-trip-moderate {
				temperature = <55000>;
				hysteresis = <2000>;
				type = "passive";
			};

			/* Оригинальный trip - 60°C */
			cpus_trip: cpus-trip {
				temperature = <60000>;
				hysteresis = <0>;
				type = "passive";
			};

			modem_trip0: modem-trip0 {
				temperature = <70000>;
				hysteresis = <2000>;
				type = "passive";
			};

			modem_trip1: modem-trip1 {
				temperature = <72000>;
				hysteresis = <3000>;
				type = "passive";
			};

			modem_trip2: modem-trip2 {
				temperature = <75000>;
				hysteresis = <4000>;
				type = "critical";
			};
		};

		cooling-maps {
			/* ══════ 45-50°C: Очень мягкое ограничение ══════ */
			skin_cpu0_early {
				trip = <&skin_trip_early>;
				cooling-device = <&CPU0 0 1>;
			};
			skin_cpu4_early {
				trip = <&skin_trip_early>;
				cooling-device = <&CPU4 0 1>;
			};

			/* ══════ 50-55°C: Мягкое ограничение ══════ */
			skin_cpu0_mild {
				trip = <&skin_trip_mild>;
				cooling-device = <&CPU0 1 2>;
			};
			skin_cpu4_mild {
				trip = <&skin_trip_mild>;
				cooling-device = <&CPU4 1 2>;
			};
			skin_gpu_mild {
				trip = <&skin_trip_mild>;
				cooling-device = <&msm_gpu 0 1>;
			};

			/* ══════ 55-60°C: Умеренное ограничение ══════ */
			skin_cpu0_moderate {
				trip = <&skin_trip_moderate>;
				cooling-device = <&CPU0 2 3>;
			};
			skin_cpu4_moderate {
				trip = <&skin_trip_moderate>;
				cooling-device = <&CPU4 2 3>;
			};
			skin_gpu_moderate {
				trip = <&skin_trip_moderate>;
				cooling-device = <&msm_gpu 1 2>;
			};

			/* ══════ 60°C+: Сильное ограничение ══════ */
			skin_cpu0 {
				trip = <&cpus_trip>;
				cooling-device = <&CPU0 THERMAL_NO_LIMIT 3>;
			};
			skin_cpu1 {
				trip = <&cpus_trip>;
				cooling-device = <&CPU1 THERMAL_NO_LIMIT 3>;
			};
			skin_cpu2 {
				trip = <&cpus_trip>;
				cooling-device = <&CPU2 THERMAL_NO_LIMIT 3>;
			};
			skin_cpu3 {
				trip = <&cpus_trip>;
				cooling-device = <&CPU3 THERMAL_NO_LIMIT 3>;
			};
			skin_cpu4 {
				trip = <&cpus_trip>;
				cooling-device = <&CPU4 THERMAL_NO_LIMIT 3>;
			};
			skin_cpu5 {
				trip = <&cpus_trip>;
				cooling-device = <&CPU5 THERMAL_NO_LIMIT 3>;
			};
			skin_cpu6 {
				trip = <&cpus_trip>;
				cooling-device = <&CPU6 THERMAL_NO_LIMIT 3>;
			};
			skin_cpu7 {
				trip = <&cpus_trip>;
				cooling-device = <&CPU7 THERMAL_NO_LIMIT 3>;
			};
			skin_gpu {
				trip = <&cpus_trip>;
				cooling-device = <&msm_gpu 2 3>;
			};

			/* ══════ Modem throttling ══════ */
			modem_lvl1 {
				trip = <&modem_trip1>;
				cooling-device = <&modem_pa 2 2>;
			};
			modem_lvl2 {
				trip = <&modem_trip2>;
				cooling-device = <&modem_pa 3 3>;
			};
			modem_proc_lvl1 {
				trip = <&modem_trip0>;
				cooling-device = <&modem_proc 1 1>;
			};
			modem_proc_lvl2 {
				trip = <&modem_trip2>;
				cooling-device = <&modem_proc 3 3>;
			};
		};
	};
};
